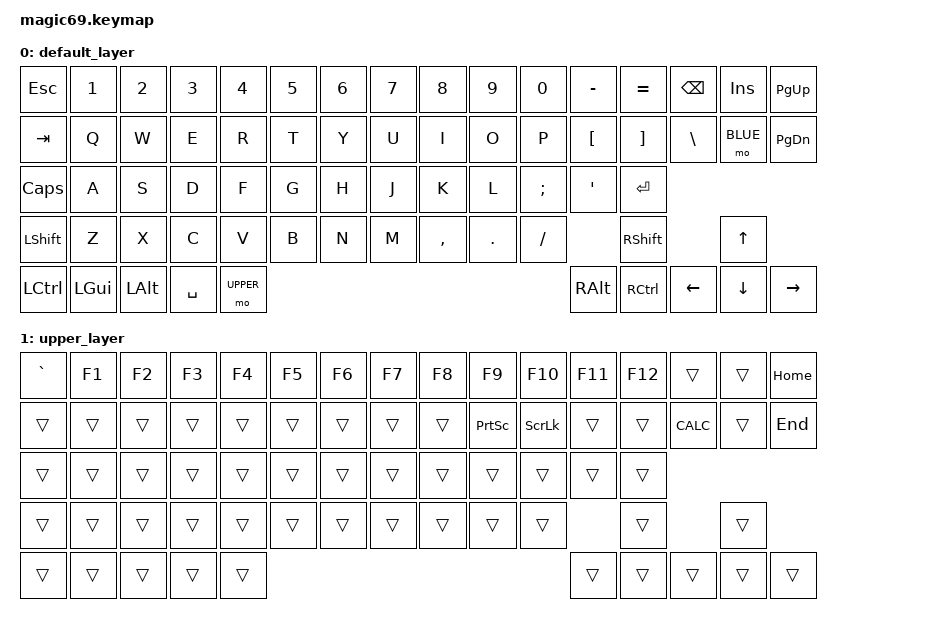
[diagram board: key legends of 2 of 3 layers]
#include <behaviors.dtsi>
#include <dt-bindings/zmk/keys.h>
#include <dt-bindings/zmk/bt.h>

// FN LAYER MODS
#define DEFAULT 0
#define UPPER 1
#define BLUE 2
/ {
    keymap {
        compatible = "zmk,keymap";

        default_layer {
                // ------------------------------------------------------------------------------------------------------------------------------
                // | COL1  | COL2 | COL3 | COL4 | COL5 | COL6 | COL7  | COL8  | COL9 | COL10| COL11 | COL12 | COL13  |   COL14   | COL15| COL16 |
                // |       |      |      |      |      |      |       |       |      |      |       |       |        |           |      |       |
                // | ESC   |  1   |  2   |  3   |  4   |  5   |   6   |  7    |  8   |  9   |   0   | DASH  | EQUALS | BACKSPACE |  INS | PGUP  |  
                // | TAB   |  Q   |  W   |  E   |  R   |  T   |   Y   |  U    |  I   |  O   |   P   |  [    |   ]    |      \    |  DEL | PGDN  |
                // | CAPS  |  A   |  S   |  D   |  F   |  G   |   H   |  J    |  K   |  L   |   ;   |  '    | ENTER  | _________ | ___  | _____ | 
                // | SHIFT |  Z   |  X   |  C   |  V   |  B   |   N   |  M    |  ,   |  .   |   /   |  ___  | SHIFT  | _________ | UP   | _____ |
                // | LCTL  | LGUI | LALT | ____ | ____ | SPACE| _____ |  ____ | ____ | FN   | RALT  | RCTRL | _____  |    LEFT   | DOWN | RIGHT |
                // ------------------------------------------------------------------------------------------------------------------------------


            bindings = <
                &kp ESC    &kp N1       &kp N2      &kp N3   &kp N4     &kp N5      &kp N6      &kp N7  &kp N8      &kp N9      &kp N0      &kp MINUS  &kp EQUAL &kp BSPC &kp INS &kp PG_UP
                &kp TAB    &kp Q        &kp W       &kp E    &kp R      &kp T       &kp Y       &kp U   &kp I       &kp O       &kp P       &kp LBKT   &kp RBKT  &kp BSLH &mo BLUE &kp PG_DN
                &kp CLCK   &kp A        &kp S       &kp D    &kp F      &kp G       &kp H       &kp J   &kp K       &kp L       &kp SEMI    &kp APOS   &kp ENTER  
                &kp LSHIFT &kp Z        &kp X       &kp C    &kp V      &kp B       &kp N       &kp M   &kp COMMA   &kp DOT     &kp FSLH               &kp RSHIFT         &kp UP          
                &kp LCTRL  &kp LGUI     &kp LALT                        &kp SPACE                                   &mo UPPER   &kp RALT    &kp RCTRL            &kp LEFT &kp DOWN &kp RIGHT
            >;
        };
        upper_layer {
                // ------------------------------------------------------------------------------------------------------------------------------
                // | COL1  | COL2 | COL3 | COL4 | COL5 | COL6 | COL7  | COL8  | COL9 | COL10| COL11 | COL12 | COL13  |   COL14   | COL15| COL16 |
                // |       |      |      |      |      |      |       |       |      |      |       |       |        |           |      |       |
                // | `     |  F1  |  F2  |  F3  |  F4  |  F5  |   F6  |  F7   |  F8  |  F9  |   F10 | F11   | F12    | TRANS     | TRANS| HOME  |  
                // | TRANS |TRANS |TRANS |TRANS | TRANS| TRANS|TRANS  |  TRANS| TRANS| PRTSC|  SLCK | TRANS | CALC   |  TRANS    | TRANS| END   |
                // | TRANS | TRANS|TRANS |TRANS |TRANS |TRANS |TRANS  |TRANS  |TRANS |TRANS |  HOME |TRANS  | TRANS  | _________ | ___  | _____ | 
                // | TRANS |TRANS |TRANS |TRANS | TRANS|TRANS |TRANS  | TRANS |TRANS |TRANS | END   |  ___  | TRANS  | _________ | TRANS| _____ |
                // | TRANS | TRANS| TRANS| ____ | ____ | boot | _____ |  ____ | ____ | TRANS| TRANS | TRANS | _____  |    TRANS  | TRANS | TRANS|
                // ------------------------------------------------------------------------------------------------------------------------------


            bindings = <
                &kp GRAVE  &kp F1       &kp F2      &kp F3   &kp F4     &kp F5      &kp F6      &kp F7  &kp F8      &kp F9      &kp F10     &kp F11  &kp F12   &trans     &trans &kp HOME
                &trans     &trans       &trans      &trans   &trans     &trans      &trans      &trans  &trans      &kp PSCRN   &kp SLCK    &trans   &trans    &kp K_CALC &trans &kp END
                &trans     &trans       &trans      &trans   &trans     &trans      &trans      &trans  &trans      &trans      &trans      &trans   &trans  
                &trans     &trans       &trans      &trans   &trans     &trans      &trans      &trans  &trans      &trans      &trans      &trans                   &trans          
                &trans     &trans       &trans                          &trans                                 &trans      &trans      &trans          &trans   &trans &trans
            >;
        };
        bluetooth_layer {
                // ------------------------------------------------------------------------------------------------------------------------------
                // | COL1  | COL2 | COL3 | COL4 | COL5 | COL6 | COL7  | COL8  | COL9 | COL10| COL11 | COL12 | COL13  |   COL14   | COL15| COL16 |
                // |       |      |      |      |      |      |       |       |      |      |       |       |        |           |      |       |
                // | TRANS |TRANS | TRANS| TRANS| TRANS| TRANS| TRANS | TRANS | TRANS| TRANS|  TRANS| TRANS | TRANS  | TRANS     | TRANS| TRANS |  
                // | TRANS |TRANS |TRANS |TRANS | TRANS| TRANS|TRANS  |  TRANS| TRANS| TRANS| TRANS | TRANS | TRANS  |  TRANS    | TRANS| TRANS |
                // | TRANS | TRANS|TRANS |TRANS |TRANS |TRANS |TRANS  |TRANS  |TRANS |TRANS | TRANS |TRANS  | TRANS  | _________ | ___  | _____ | 
                // | TRANS |TRANS |TRANS |TRANS | TRANS|TRANS |TRANS  | TRANS |TRANS |TRANS | TRANS |  ___  | TRANS  | _________ | TRANS| _____ |
                // | TRANS | TRANS| TRANS| ____ | ____ | TRANS| _____ |  ____ | ____ | TRANS| TRANS | TRANS | _____  |    TRANS  | TRANS | TRANS|
                // ------------------------------------------------------------------------------------------------------------------------------


            bindings = <
                &bootloader    &trans       &trans      &trans   &trans     &trans      &trans      &trans  &trans      &trans      &trans      &trans &bt BT_SEL 0 &bt BT_SEL 1 &bt BT_SEL 2 &bt BT_SEL 3 &bt BT_SEL 4 
                &trans     &trans       &trans      &trans   &trans     &trans      &trans      &trans  &trans      &trans      &trans      &trans   &trans    &trans     &trans &bt BT_CLR
                &trans     &trans       &trans      &trans   &trans     &trans      &trans      &trans  &trans      &trans      &trans      &trans   &trans 
                &trans     &trans       &trans      &trans   &trans     &trans      &trans      &trans  &trans      &trans      &trans      &trans              &trans          
                &trans     &trans       &trans                          &trans                                      &trans      &trans      &trans     &trans   &trans &trans
            >;
        };
    };
};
